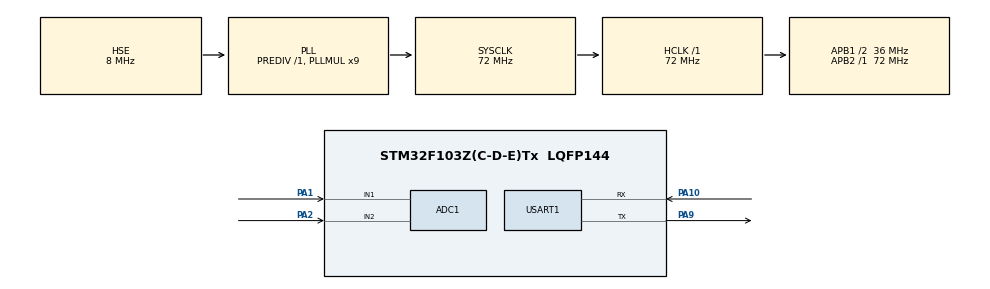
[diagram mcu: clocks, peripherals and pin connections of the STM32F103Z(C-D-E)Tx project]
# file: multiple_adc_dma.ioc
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ADC1.Channel-1\#ChannelRegularConversion=ADC_CHANNEL_1
ADC1.Channel-2\#ChannelRegularConversion=ADC_CHANNEL_2
ADC1.ContinuousConvMode=ENABLE
ADC1.DiscontinuousConvMode=DISABLE
ADC1.NbrOfConversion=2
ADC1.NbrOfConversionFlag=1
ADC1.Rank-1\#ChannelRegularConversion=1
ADC1.Rank-2\#ChannelRegularConversion=2
ADC1.SamplingTime-1\#ChannelRegularConversion=ADC_SAMPLETIME_239CYCLES_5
ADC1.SamplingTime-2\#ChannelRegularConversion=ADC_SAMPLETIME_239CYCLES_5
ADC1.master=1
Dma.ADC1.0.Direction=DMA_PERIPH_TO_MEMORY
Dma.ADC1.0.Instance=DMA1_Channel1
Dma.ADC1.0.MemDataAlignment=DMA_MDATAALIGN_HALFWORD
Dma.ADC1.0.MemInc=DMA_MINC_ENABLE
Dma.ADC1.0.Mode=DMA_CIRCULAR
Dma.ADC1.0.PeriphDataAlignment=DMA_PDATAALIGN_HALFWORD
Dma.ADC1.0.PeriphInc=DMA_PINC_DISABLE
Dma.ADC1.0.Priority=DMA_PRIORITY_LOW
Dma.Request0=ADC1
Mcu.Family=STM32F1
Mcu.Name=STM32F103Z(C-D-E)Tx
Mcu.Package=LQFP144
NVIC.DMA1_Channel1_IRQn=true\:0\:0\:false\:false\:true\:false\:true
NVIC.PriorityGroup=NVIC_PRIORITYGROUP_4
OSC_IN.Mode=HSE-External-Oscillator
OSC_IN.Signal=RCC_OSC_IN
OSC_OUT.Mode=HSE-External-Oscillator
OSC_OUT.Signal=RCC_OSC_OUT
PA1.Signal=SharedAnalog_PA1
PA10.Mode=Asynchronous
PA10.Signal=USART1_RX
PA13.Mode=Serial_Wire
PA13.Signal=SYS_JTMS-SWDIO
PA14.Mode=Serial_Wire
PA14.Signal=SYS_JTCK-SWCLK
PA2.Signal=SharedAnalog_PA2
PA9.Mode=Asynchronous
PA9.Signal=USART1_TX
ProjectManager.HeapSize=0x200
ProjectManager.StackSize=0x400
ProjectManager.TargetToolchain=MDK-ARM V5.27
RCC.ADCPresc=RCC_ADCPCLK2_DIV6
RCC.AHBFreq_Value=72000000
RCC.APB1CLKDivider=RCC_HCLK_DIV2
RCC.APB1Freq_Value=36000000
RCC.APB1TimFreq_Value=72000000
RCC.APB2Freq_Value=72000000
RCC.APB2TimFreq_Value=72000000
RCC.HCLKFreq_Value=72000000
RCC.PLLMUL=RCC_PLL_MUL9
RCC.PLLSourceVirtual=RCC_PLLSOURCE_HSE
RCC.SYSCLKFreq_VALUE=72000000
RCC.SYSCLKSource=RCC_SYSCLKSOURCE_PLLCLK
RCC.USBFreq_Value=72000000
SH.SharedAnalog_PA1.0=GPIO_Analog
SH.SharedAnalog_PA1.1=ADC1_IN1,IN1
SH.SharedAnalog_PA2.0=GPIO_Analog
SH.SharedAnalog_PA2.1=ADC1_IN2,IN2
USART1.VirtualMode=VM_ASYNC
board=custom

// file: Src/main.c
/* USER CODE BEGIN Header */
/**
  ******************************************************************************
  * @file           : main.c
  * @brief          : Main program body
  ******************************************************************************
  * @attention
  *
  * <h2><center>&copy; Copyright (c) 2021 STMicroelectronics.
  * All rights reserved.</center></h2>
  *
  * This software component is licensed by ST under BSD 3-Clause license,
  * the "License"; You may not use this file except in compliance with the
  * License. You may obtain a copy of the License at:
  *                        opensource.org/licenses/BSD-3-Clause
  *
  ******************************************************************************
  */
/* USER CODE END Header */

#include "main.h"
#include "adc.h"
#include "dma.h"
#include "usart.h"
#include "gpio.h"

void SystemClock_Config(void);
/* USER CODE BEGIN PFP */
uint16_t ad_value[2];
/* USER CODE END PFP */

int main(void)
{

  /* MCU Configuration--------------------------------------------------------*/

  /* Reset of all peripherals, Initializes the Flash interface and the Systick. */
  HAL_Init();

  /* Configure the system clock */
  SystemClock_Config();

  /* Initialize all configured peripherals */
  MX_GPIO_Init();
  MX_DMA_Init();
  MX_ADC1_Init();
  MX_USART1_UART_Init();
  /* USER CODE BEGIN 2 */
	HAL_ADC_Start_DMA(&hadc1,(uint32_t*)(ad_value),2);
  /* USER CODE END 2 */

  /* Infinite loop */
  while (1)
  {

  }
}

/* USER CODE BEGIN 4 */
void HAL_ADC_ConvCpltCallback(ADC_HandleTypeDef* hadc)
{
	if(hadc == &hadc1)
	{
		printf("adc value[0]:%f\r\n",ad_value[0]/4096.0*3.3);
		printf("adc value[1]:%f\r\n",ad_value[1]/4096.0*3.3);
	}
}
/* USER CODE END 4 */

void SystemClock_Config(void)
{
  RCC_OscInitTypeDef RCC_OscInitStruct = {0};
  RCC_ClkInitTypeDef RCC_ClkInitStruct = {0};
  RCC_PeriphCLKInitTypeDef PeriphClkInit = {0};

  /** Initializes the CPU, AHB and APB busses clocks
  */
  RCC_OscInitStruct.OscillatorType = RCC_OSCILLATORTYPE_HSE;
  RCC_OscInitStruct.HSEState = RCC_HSE_ON;
  RCC_OscInitStruct.HSEPredivValue = RCC_HSE_PREDIV_DIV1;
  RCC_OscInitStruct.HSIState = RCC_HSI_ON;
  RCC_OscInitStruct.PLL.PLLState = RCC_PLL_ON;
  RCC_OscInitStruct.PLL.PLLSource = RCC_PLLSOURCE_HSE;
  RCC_OscInitStruct.PLL.PLLMUL = RCC_PLL_MUL9;
  if (HAL_RCC_OscConfig(&RCC_OscInitStruct) != HAL_OK)
  {
    Error_Handler();
  }
  /** Initializes the CPU, AHB and APB busses clocks
  */
  RCC_ClkInitStruct.ClockType = RCC_CLOCKTYPE_HCLK|RCC_CLOCKTYPE_SYSCLK
                              |RCC_CLOCKTYPE_PCLK1|RCC_CLOCKTYPE_PCLK2;
  RCC_ClkInitStruct.SYSCLKSource = RCC_SYSCLKSOURCE_PLLCLK;
  RCC_ClkInitStruct.AHBCLKDivider = RCC_SYSCLK_DIV1;
  RCC_ClkInitStruct.APB1CLKDivider = RCC_HCLK_DIV2;
  RCC_ClkInitStruct.APB2CLKDivider = RCC_HCLK_DIV1;

  if (HAL_RCC_ClockConfig(&RCC_ClkInitStruct, FLASH_LATENCY_2) != HAL_OK)
  {
    Error_Handler();
  }
  PeriphClkInit.PeriphClockSelection = RCC_PERIPHCLK_ADC;
  PeriphClkInit.AdcClockSelection = RCC_ADCPCLK2_DIV6;
  if (HAL_RCCEx_PeriphCLKConfig(&PeriphClkInit) != HAL_OK)
  {
    Error_Handler();
  }
}

void Error_Handler(void)
{
}

/************************ (C) COPYRIGHT STMicroelectronics *****END OF FILE****/
